# pse84 register map
Vendor: Infineon Technologies; Series: PSE84; File version: 1.0
CPU: CM33 r0p1, little endian, MPU, FPU, VTOR, 3 interrupt priority bits
Registers are 32-bit, read-write, reset 0x0 unless marked. A register's access mark holds for its fields unless they carry their own. Offsets are from the block's base; [hi:lo] are bit positions; lines under a group give offsets from that group; {n}, {i} and the like mark numbered series; 'fields as' and 'values as' point back to an identical list; <NAME> marks a mode.

## SMIF0 (part 3 of 3) — SMIF subsystem (1 SMIF cores, no bridge, 1 cache_block and 1 Q_LPI expander)
Base 0x44440000
Same registers: SMIF1 0x44480000
0x20000 CORE group — Serial Memory Interface
  {0x800+0x80*j} DEVICE[{j}] (j=0..3) group — Device (only used for XIP acceses)
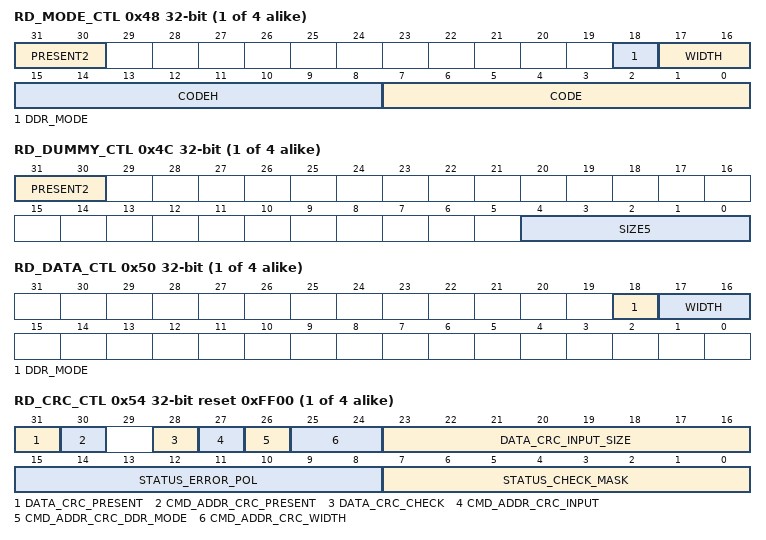
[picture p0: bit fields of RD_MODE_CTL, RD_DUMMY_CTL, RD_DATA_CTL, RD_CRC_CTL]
    0x48 RD_MODE_CTL — Read mode control
      [31:30] PRESENT2 — Presence of mode field: '0': not present '1': present (1 Byte) '2': present (2 Byte for OPI) Note: For octal data transfer with DDR mode (WIDTH='3' and DDR_MODE='1') this field needs to be set to PRESENT2='2' to generate a mode field (or to PRESENT2='0').
      [18] DDR_MODE — Mode of transfer rate.
      [17:16] WIDTH — Width of transfer.
      [15:8] CODEH — Mode high byte code. This field specifies the most significant mode byte, sent before the least significant mode byte (CODE). It is only used when PRESENT2 = '2'.
      [7:0] CODE — Mode byte code. Note: If a mode field is present (PRESENT='1') for octal data transfer with DDR mode (WIDTH='3' and DDR_MODE='1') the CODE is sent twice.
    0x4C RD_DUMMY_CTL — Read dummy control
      [31:30] PRESENT2 — Presence of dummy cycles: '0': not present '1': present '2': present - Dummy cycles are doubled when RWDS refresh indicator is high during CA cycle. (HyperRAM variable latency mode) Notes: - If transmitting command, address and mode fields in SDR mode (driving data between falling edges of spihb_clk_out) and the memory is driving read data in DDR mode (based on memory type and transmitted command), then there must be at least 1 latency / dummy cycle specified (RD_DUMMY_CTL.PRESENT2 > 0') to prevent controller and memory driving data signals at the same time. The same is true for the theoretical (practically irrelevant case) of transmitting at least one of the command, address and mode fields in DDR mode but receiving data from the memory in SDR mode. - When using the RWDS / DQS based capturing scheme (CTL2.RX_CAPTURE_MODE), then there is a minimum number of latency / dummy cycles required (RD_DUMMY_CTL.PRESENT2 > 0). For the Hyperbus protocol (DDR_CTL.SIZE3=7) at least 1 latency / dummy cycle has to be specified, for SPI with DQS capturing at least 2 latency / dummy cycles need to be selected (RD_DUMMY_CTL.SIZE5 > 0, exception see following note). - In case of falling edge RWDS / DQS capturing (CTL2.RX_CAPTURE_MODE) and SDR mode, SW should reduce the number of dummy cycles by 1 compared to the latency cycles required by the memory device. -DDR read commands need at least one dummy cycle -For Hyperbus, set RD DUMMY_CTL.SIZE5=initial latency cycles-2
      [4:0] SIZE5 — Number of dummy cycles (minus 1): '0': 1 cycles ... '31': 32 cycles. Note: this field specifies dummy cycles, not dummy Bytes!
    0x50 RD_DATA_CTL — Read data control
      [18] DDR_MODE — Mode of transfer rate.
      [17:16] WIDTH — Width of transfer.
    0x54 RD_CRC_CTL reset 0xFF00 — Read Bus CRC control
      [31] DATA_CRC_PRESENT — Presence of data CRC field: '0': not present '1': present Note: Width and data transfer mode (SDR or DDR) of read data CRC fields are the same as for the associated read data fields, i.e. are specified by RD_DATA_CTL.WIDTH and RD_DATA_CTL.DDR_MODE.
      [30] CMD_ADDR_CRC_PRESENT — Presence of command / address CRC field: '0': not present '1': present Note: For octal data transfer with DDR mode (RD_CRC_CTL.WIDTH='3' and RD_CRC_CTL.DDR_MODE='1') the command / address CRC byte is sent twice, otherwise the command / address CRC byte is only sent once.
      [28] DATA_CRC_CHECK
      [27] CMD_ADDR_CRC_INPUT — Specifies which fields are included in the command / address CRC generation. '0': The command / address CRC field is generated over the address and (if present) mode fields only. '1': The command / address CRC field is generated over the command, address and (if present) mode fields.
      [26] CMD_ADDR_CRC_DDR_MODE — Mode of transfer rate of command / address CRC field.
      [25:24] CMD_ADDR_CRC_WIDTH — Width of command / address CRC field.
      [23:16] DATA_CRC_INPUT_SIZE — Number of input data bytes for CRC generation (minus 1), i.e. number of data bytes over which the data CRC field is generated (minus 1): '0': 1 byte ... '255': 256 bytes. Note: For octal data transfer with DDR mode (RD_DATA_CTL.WIDTH='3' and RD_DATA_CTL.DDR_MODE='1') the number of bytes for CRC generation must be even (i.e. DATA_CRC_INPUT_SIZE must be odd).
      [15:8] STATUS_ERROR_POL — Specifies the polarity of the Functional Safety Status field bits. There is 1 polarity bit for each Functional Safety Status bit. '0': The associated Functional Safety Status bit is active-low. '1': The associated Functional Safety Status bit is active-high.
      [7:0] STATUS_CHECK_MASK — Specifies which of the Functional Safety Status field bits are checked. There is 1 mask bit for each Functional Safety Status bit. '0': The associated Functional Safety Status bit is not checked. '1': The associated Functional Safety Status bit is checked. If the received Funciontal Safety Status bit = Functional Safety Status Error Polarity (STATUS_ERROR_POLARITY), then a Functional Safety Status error interrupt and a XIP bus error response is generated.
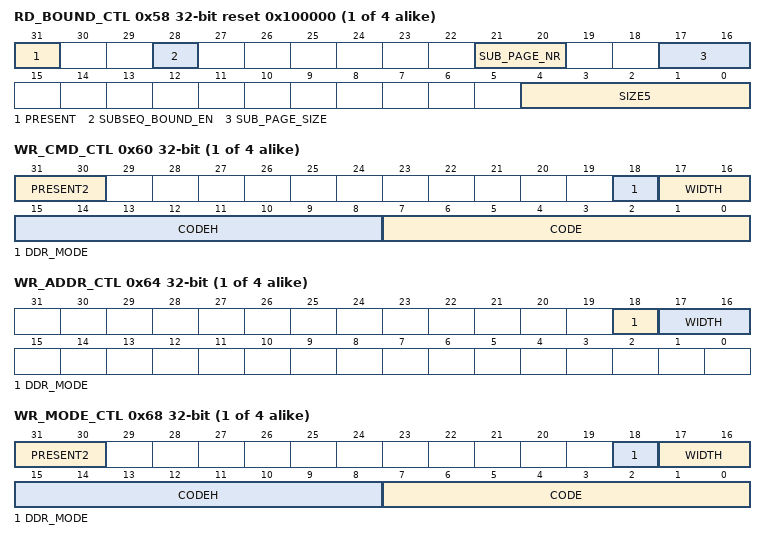
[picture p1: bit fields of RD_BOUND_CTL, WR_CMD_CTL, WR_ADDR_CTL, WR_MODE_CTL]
    0x58 RD_BOUND_CTL reset 0x100000 — Read boundary control
      [31] PRESENT — Presence of first page boundary latency cycles: '0': not present '1': present
      [28] SUBSEQ_BOUND_EN — Enable subsequent page boundary latency cycles. '0': Disabled. The page crossing latency cycles are only generated when crossing the first page boundary (i.e. the first time when the SUB_PAGE_NRth sub page boundary is crossed, e.g. with 2 sub pages per page when the 2nd sub page boundary is crossed). '1': Enabled. The page crossing latency cycles are generated when crossing the first and subsequent page boundaries (i.e. every time when a SUB_PAGE_NRth sub page boundary is crossed, e.g. with 2 sub pages per page when the 2nd, 4th, 6th, ... sub page boundary is crossed). Note: This only applies when the number of base latency cycles (SIZE5+1) is greater than the size of a page (base_latency > page_size). Must be set to 0 otherwise.
      [21:20] SUB_PAGE_NR — Specifies the number of sub pages per page. '0': 1 sub pages per page, i.e. page_size = sub_page_size '1': 2 sub pages per page, i.e. page_size = 2 x sub_page_size '2': 4 sub pages per page, i.e. page_size = 4 x sub_page_size '3': 8 sub pages per page, i.e. page_size = 8 x sub_page_size
      [17:16] SUB_PAGE_SIZE — Specifies the size of a memory sub page 'sub_page_size'. '0': sub_page_size = 8 words = 16 bytes (default). '1': sub_page_size = 16 words = 32 bytes. '2': sub_page_size = 32 words = 64 bytes. '3': sub_page_size = 64 words = 128 bytes.
      [4:0] SIZE5 — Number of base latency cycles (minus 1) used for calculating the number of fist page boundary crossing latency cycles: '0': base_latency = 1 cycles ... '31': base_latency = 32 cycles. The actual latency cycles when crossing the first page boundary depend on the start address of the transaction and is calculated as follows: if ((page_size - base_latency) < Start_Addr & (sub_page_size - 1)) { ((Start_Addr & (sub_page_size - 1)) - page_size + base_latency) } else { 0 }
    0x60 WR_CMD_CTL — Write command control
      [31:30] PRESENT2 — Presence of command field: '0': not present '1': present (1 Byte) '2': present (2 Byte for OPI) Note: For octal data transfer with DDR mode (WIDTH='3' and DDR_MODE='1') either the HB protocol needs to be selected (by ADDR_CTL.SIZE3='7') or this field needs to be set to PRESENT2='2'.
      [18] DDR_MODE — Mode of transfer rate.
      [17:16] WIDTH — Width of transfer.
      [15:8] CODEH — Command high byte code. This field specifies the most significant command byte, sent before the least significant command byte (CODE). It is only used when PRESENT2 = '2'.
      [7:0] CODE — Command byte code.
    0x64 WR_ADDR_CTL — Write address control
      fields as CORE.DEVICE[0].RD_DATA_CTL
    0x68 WR_MODE_CTL — Write mode control
      [31:30] PRESENT2 — Presence of mode field: '0': not present '1': present (1 Byte) '2': present (2 Byte for OPI) Note: For octal data transfer with DDR mode (WIDTH='3' and DDR_MODE='1') this field needs to be set to PRESENT2='2' to generate a mode field (or to PRESENT2='0').
      [18] DDR_MODE — Mode of transfer rate.
      [17:16] WIDTH — Width of transfer.
      [15:8] CODEH — Mode high byte code. This field specifies the most significant mode byte, sent before the least significant mode byte (CODE). It is only used when PRESENT2 = '2'.
      [7:0] CODE — Mode byte code.
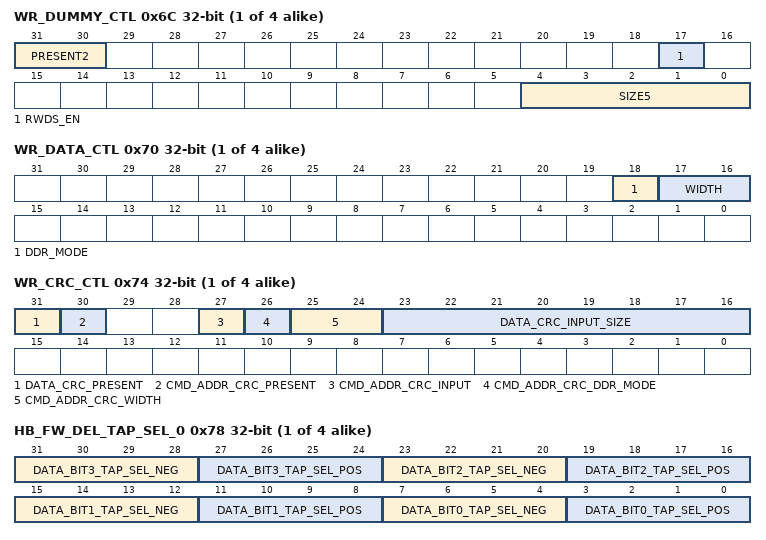
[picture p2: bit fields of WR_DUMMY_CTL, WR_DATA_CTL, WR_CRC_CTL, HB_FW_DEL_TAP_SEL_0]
    0x6C WR_DUMMY_CTL — Write dummy control
      [31:30] PRESENT2 — Presence of dummy cycles: '0': not present '1': present '2': present - Dummy cycles are doubled when RWDS refresh indicator is high during CA cycle. (HyperRAM variable latency mode)
      [17] RWDS_EN — Read-Write-Data-Strobe Enable. Specifies whether the RWDS output signal should be driven starting in the last dummy cycle until DESELECT. This is needed for write transactions with byte masking via RWDS (e.g. Hyperbus). '0': do not drive RWDS output '1': drive RWDS output starting in last dummy cycle until DESELECT Note: this field is located in the WR_DUMMY_CTL register (and not in the WR_DATA_CTL register) since the RWDS signal needs to be driven already in the last dummy cycle.
      [4:0] SIZE5 — Number of dummy cycles (minus 1): '0': 1 cycles ... '31': 32 cycles.
    0x70 WR_DATA_CTL — Write data control
      fields as CORE.DEVICE[0].RD_DATA_CTL
    0x74 WR_CRC_CTL — Write Bus CRC control
      [31] DATA_CRC_PRESENT — Presence of data CRC field: '0': not present '1': present Note: Width and data transfer mode (SDR or DDR) of read data CRC fields are the same as for the associated read data fields, i.e. are specified by RD_DATA_CTL.WIDTH and RD_DATA_CTL.DDR_MODE. Note: For octal data transfer with DDR mode (RD_DATA_CTL.WIDTH='3' and RD_DATA_CTL.DDR_MODE='1') the data CRC byte is sent twice, otherwise the data CRC byte is only sent once.
      [30] CMD_ADDR_CRC_PRESENT — Presence of command / address CRC field: '0': not present '1': present Note: For octal data transfer with DDR mode (RD_CRC_CTL.WIDTH='3' and RD_CRC_CTL.DDR_MODE='1') the command / address CRC byte is sent twice, otherwise the command / address CRC byte is only sent once.
      [27] CMD_ADDR_CRC_INPUT — Specifies which fields are included in the command / address CRC generation. '0': The command / address CRC field is generated over the address and (if present) mode fields only. '1': The command / address CRC field is generated over the command, address and (if present) mode fields.
      [26] CMD_ADDR_CRC_DDR_MODE — Mode of transfer rate of command / address CRC field.
      [25:24] CMD_ADDR_CRC_WIDTH — Width of command / address CRC field.
      [23:16] DATA_CRC_INPUT_SIZE — Number of input data bytes for CRC generation (minus 1), i.e. number of data bytes over which the data CRC field is generated (minus 1): '0': 1 byte ... '255': 256 bytes. Note: For octal data transfer with DDR mode (WR_DATA_CTL.WIDTH='3' and WR_DATA_CTL.DDR_MODE='1') the number of bytes for CRC generation must be even (i.e. DATA_CRC_INPUT_SIZE must be odd).
    0x78 HB_FW_DEL_TAP_SEL_0 — HB FW Calibration Delay Tap Select 0
      [31:28] DATA_BIT3_TAP_SEL_NEG — HB FW Calibration: Delay line tap select for spi_data[3], NEG Clock Phase (note the mapping of spi_data to IO in DEVICE.CTL.DATA_SEL). See DATA_BIT0_TAP_SEL.
      [27:24] DATA_BIT3_TAP_SEL_POS — HB FW Calibration: Delay line tap select for spi_data[3], POS Clock Phase (note the mapping of spi_data to IO in DEVICE.CTL.DATA_SEL). See DATA_BIT0_TAP_SEL.
      [23:20] DATA_BIT2_TAP_SEL_NEG — HB FW Calibration: Delay line tap select for spi_data[2], NEG Clock Phase (note the mapping of spi_data to IO in DEVICE.CTL.DATA_SEL). See DATA_BIT0_TAP_SEL.
      [19:16] DATA_BIT2_TAP_SEL_POS — HB FW Calibration: Delay line tap select for spi_data[2], POS Clock Phase (note the mapping of spi_data to IO in DEVICE.CTL.DATA_SEL). See DATA_BIT0_TAP_SEL.
      [15:12] DATA_BIT1_TAP_SEL_NEG — HBs FW Calibration: Delay line tap select for spi_data[1], NEG Clock Phase (note the mapping of spi_data to IO in DEVICE.CTL.DATA_SEL). See DATA_BIT0_TAP_SEL.
      [11:8] DATA_BIT1_TAP_SEL_POS — HB FW Calibration: Delay line tap select for spi_data[1], POS Clock Phase (note the mapping of spi_data to IO in DEVICE.CTL.DATA_SEL). See DATA_BIT0_TAP_SEL.
      [7:4] DATA_BIT0_TAP_SEL_NEG — HB FW Calibration: Delay line tap select for spi_data[0], NEG Clock Phase (note the mapping of spi_data to IO in DEVICE.CTL.DATA_SEL). See DATA_BIT0_TAP_SEL.
      [3:0] DATA_BIT0_TAP_SEL_POS — HB FW Calibration tap select for spi_data[0], POS clock Phase (note the mapping of spi_data to IO in DEVICE.CTL.DATA_SEL).
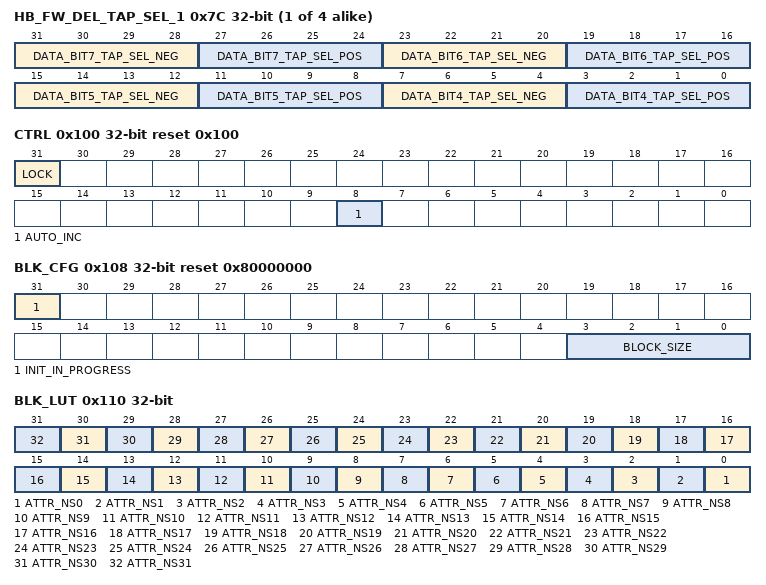
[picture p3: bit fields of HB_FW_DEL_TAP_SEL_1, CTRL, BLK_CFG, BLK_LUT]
    0x7C HB_FW_DEL_TAP_SEL_1 — HB FW Calibration Delay Tap Select 1
      [31:28] DATA_BIT7_TAP_SEL_NEG — HB FW Calibration: Delay line tap select for spi_data[7], NEG Clock Phase (note the mapping of spi_data to IO in DEVICE.CTL.DATA_SEL). See DATA_BIT0_TAP_SEL.
      [27:24] DATA_BIT7_TAP_SEL_POS — HB FW Calibration: Delay line tap select for spi_data[7], POS Clock Phase (note the mapping of spi_data to IO in DEVICE.CTL.DATA_SEL). See DATA_BIT0_TAP_SEL.
      [23:20] DATA_BIT6_TAP_SEL_NEG — HB FW Calibration: Delay line tap select for spi_data[6], NEG Clock Phase (note the mapping of spi_data to IO in DEVICE.CTL.DATA_SEL). See DATA_BIT0_TAP_SEL.
      [19:16] DATA_BIT6_TAP_SEL_POS — HB FW Calibration: Delay line tap select for spi_data[6], POS Clock Phase (note the mapping of spi_data to IO in DEVICE.CTL.DATA_SEL). See DATA_BIT0_TAP_SEL.
      [15:12] DATA_BIT5_TAP_SEL_NEG — HBs FW Calibration: Delay line tap select for spi_data[5], NEG Clock Phase (note the mapping of spi_data to IO in DEVICE.CTL.DATA_SEL). See DATA_BIT0_TAP_SEL.
      [11:8] DATA_BIT5_TAP_SEL_POS — HB FW Calibration: Delay line tap select for spi_data[5], POS Clock Phase (note the mapping of spi_data to IO in DEVICE.CTL.DATA_SEL). See DATA_BIT0_TAP_SEL.
      [7:4] DATA_BIT4_TAP_SEL_NEG — HB FW Calibration: Delay line tap select for spi_data[4], NEG Clock Phase (note the mapping of spi_data to IO in DEVICE.CTL.DATA_SEL). See DATA_BIT0_TAP_SEL.
      [3:0] DATA_BIT4_TAP_SEL_POS — HB FW Calibration tap select for spi_data[4], POS clock Phase (note the mapping of spi_data to IO in DEVICE.CTL.DATA_SEL).
  0x3000 AXI group — Serial Memory Interface
    0x00 MPC group — MPC Memory Protection Controller registers
      0x00 CFG — Config register with error response, RegionID PPC_MPC_MAIN is the security owner PC. The error response configuration is located in CFG.RESPONSE, only one such configuration exists applying to all protection contexts in the system.
        [4] RESPONSE — Response Configuration for Security and PC violations 0: Read-Zero Write Ignore (RAZ/WI) 1: Bus Error
      0x100 CTRL reset 0x100 — Control register with lock bit and auto-increment only (Separate CTRL for each PC depends on access_pc)
        [31] LOCK — Security lockdown for this protection context. Software can set this bit but not clear it once set. When set, write operations to BLK_LUT are not possible from this protection context. Setting LOCK also blocks writes to CTRL itself (for that PC copy). All writes are ignored.
        [8] AUTO_INC — Auto-increment BLK_IDX by 1 for this protection context as a side effect of each read/write access to BLK_LUT
      0x104 BLK_MAX ro — Max value of block-based index register
        [31:0] VALUE — Maximum value of block-based index register. The number and size blocks in an MPC is design time configurable and for embedded memories defaults to covering the entire memory using 4kB blocks; See product datasheet for details on protection of external memories.
      0x108 BLK_CFG ro reset 0x80000000 — Block size & initialization in progress
        [31] INIT_IN_PROGRESS — During initialization INIT_IN_PROGRESS is '1' and MMIO register accesses to BLK_LUT is blocked (BLK_IDX increment is also ignored). The block attributes are retained in DeepSleep (and obviously Active) power mode. Initialization is only required from a power mode in which the block attributes are not retained. E.g., initialization is required for a cold boot (after a Power-on-Reset). HW initializes the block attributes: the NS attributes are set to '0' (secure), the R attributes are set to '1' (read access allowed) and the W attributes are set to '1' (write access allowed). During initialization, the MPC supports memory accesses (memory accesses are NOT blocked) with the initialization block attribute values as mentioned above. This e.g. allows MPC initialization to proceed in parallel with boot program memory accesses (as opposed to serializing the two), improving device boot time.
        [3:0] BLOCK_SIZE — Block size of individually protected blocks (0: 32B, 1: 64B, ... up to 15: 1MB) Block size= (1<<(BLOCK_SIZE+5)) The number and size blocks in an MPC is design time configurable and for embedded memories defaults to covering the entire memory using 4kB blocks; see product datasheet for details on protection of external memories.
      0x10C BLK_IDX — Index of 32-block group accessed through BLK_LUT (Separate IDX for each PC depending on access_pc)
        [31:0] VALUE — Index value for accessing block-based lookup table using BLK_LUT. Programming out of LUT range is an user error and it loops back to '0' once overflow occurs.
      0x110 BLK_LUT — NS status for 32 blocks at BLK_IDX with PC=<access_pc>
        [n] ATTR_NS{n} (n=0..31) — NS bit for block {n} based on BLK_IDX
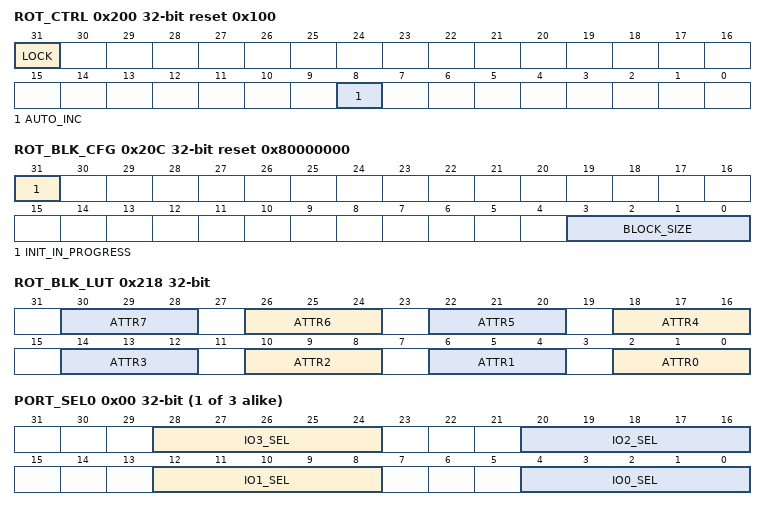
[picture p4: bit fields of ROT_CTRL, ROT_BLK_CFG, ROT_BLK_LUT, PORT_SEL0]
      0x200 ROT_CTRL reset 0x100 — Control register with lock bit and auto-increment only
        [31] LOCK — Security lockdown for the root-of-trust configuration registers. Software can set this bit but not clear it once set. When set, write operations to ROT_BLK_LUT are not possible. Write is ignored.
        [8] AUTO_INC — Auto-increment BLK_IDX by 1 for each read/write of ROT_BLK_LUT
      0x208 ROT_BLK_MAX ro — Max value of block-based index register for ROT
        [31:0] VALUE — Maximum value of block-based index register. The number and size blocks in an MPC is design time configurable and for embedded memories defaults to covering the entire memory using 4kB blocks; see product datasheet for details on protection of external memories.
      0x20C ROT_BLK_CFG ro reset 0x80000000 — Same as BLK_CFG
        [31] INIT_IN_PROGRESS — During initialization INIT_IN_PROGRESS is '1' and MMIO register accesses to ROT_BLK_LUT is RAZWI. The block attributes are retained in DeepSleep (and obviously Active) power mode. Initialization is only required from a power mode in which the block attributes are not retained. E.g., initialization is required for a cold boot (after a Power-on-Reset). HW initializes the block attributes: the NS attributes are set to '0' (secure), the R attributes are set to '1' (read access allowed) and the W attributes are set to '1' (write access allowed). During initialization, the MPC supports memory accesses (memory accesses are NOT blocked) with the initialization block attribute values as mentioned above. This e.g. allows MPC initialization to proceed in parallel with boot program memory accesses (as opposed to serializing the two), improving device boot time.
        [3:0] BLOCK_SIZE — Block size of individually protected blocks (0: 32B, 1: 64B, ...up to 15:1MB) Block size= (1<<(BLOCK_SIZE+5)) The number and size blocks in an MPC is design time configurable and for embedded memories defaults to covering the entire memory using 4kB blocks; see product datasheet for details on protection of external memories.
      0x210 ROT_BLK_IDX — Index of 8-block group accessed through ROT_BLK_LUT_*
        [31:0] VALUE — Index value for accessing block-based lookup table using ROT_BLK_LUT. Programming out of LUT range is an user error and it loops back to '0' once overflow occurs.
      0x214 ROT_BLK_PC — Protection context of 8-block group accesses through ROT_BLK_LUT
        [3:0] PC — Specify PC values for ROT_BLK_IDX and ROT_BLK_LUT
      0x218 ROT_BLK_LUT — (R,W,NS) bits for 8 blocks at ROT_BLK_IDX for PC=ROT_BKL_PC
        [4n+2:4n] ATTR{n} (n=0..7) — W/R/NS bits for block {n} indicated by ROT_BLK_IDX for ROT_BLK_PC PC
  0x4000 SMIF_HSIOM group — IO Matrix (IOM)
    {0x0+0x10*k} SMIF_PRT[{k}] (k=0..2) group — HSIOM port registers
      0x00 PORT_SEL0 — Port selection 0
        [28:24] IO3_SEL — Selects connection for IO pin 3 route.
        [20:16] IO2_SEL — Selects connection for IO pin 2 route.
        [12:8] IO1_SEL — Selects connection for IO pin 1 route.
        [4:0] IO0_SEL — Selects connection for IO pin 0 route.
          0=GPIO (GPIO controls 'out'); 1=GPIO_DSI (GPIO controls 'out', DSI controls 'output enable'); 2=DSI_DSI (DSI controls 'out' and 'output enable'); 3=DSI_GPIO (DSI controls 'out', GPIO controls 'output enable'); 4=AMUXA (Analog mux bus A); 5=AMUXB (Analog mux bus B); 6=AMUXA_DSI (Analog mux bus A, DSI control); 7=AMUXB_DSI (Analog mux bus B, DSI control); {v}=ACT_{v-8} (Active functionality {v-8}) (v=8..11); {v}=DS_{v-12} (DeepSleep functionality {v-12}) (v=12..15); {v}=ACT_{v-12} (Active functionality {v-12}) (v=16..25); 26=ACT_14 (Active functionality 14. Use this setting for AUX functionality (PRT0_PORT_SEL0 for DATA LSBs).); 27=ACT_15 (Active functionality 15. Use this setting for SMIF functionality (PRT0_PORT_SEL0 for DATA LSBs, PRT1_PORT_SEL0 for CLK, PRT2_PORT_SEL0 for RWDS).); {v}=DS_{v-24} (DeepSleep functionality {v-24}) (v=28..31)
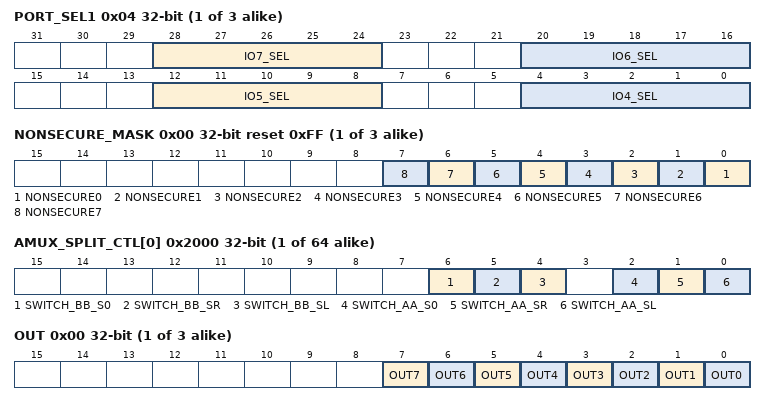
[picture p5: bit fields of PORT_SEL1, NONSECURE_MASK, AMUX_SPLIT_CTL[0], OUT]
      0x04 PORT_SEL1 — Port selection 1
        [28:24] IO7_SEL — Selects connection for IO pin 7 route.
        [20:16] IO6_SEL — Selects connection for IO pin 6 route.
        [12:8] IO5_SEL — Selects connection for IO pin 5 route.
        [4:0] IO4_SEL — Selects connection for IO pin 4 route. See PORT_SEL0 for connection details. PRT0_PORT_SEL1 is used for DATA MSBs.
    {0x1000+0x10*k} SMIF_SECURE_PRT[{k}] (k=0..2) group — HSIOM secure attribute port registers
      0x00 NONSECURE_MASK reset 0xFF
        [n] NONSECURE{n} (n=0..7) — Non-secure attribute for IO{n}. 0 - Allows Secure access only. 1 - Allows Non-secure access only.
    {0x2000+4k} AMUX_SPLIT_CTL[{k}] (k=0..63) — AMUX splitter cell control
      [6] SWITCH_BB_S0 — T-switch control for AMUXBUSB vssa/ground switch.
      [5] SWITCH_BB_SR — T-switch control for Right AMUXBUSB switch.
      [4] SWITCH_BB_SL — T-switch control for Left AMUXBUSB switch.
      [2] SWITCH_AA_S0 — T-switch control for AMUXBUSA vssa/ground switch: '0': switch open. '1': switch closed.
      [1] SWITCH_AA_SR — T-switch control for Right AMUXBUSA switch: '0': switch open. '1': switch closed.
      [0] SWITCH_AA_SL — T-switch control for Left AMUXBUSA switch: '0': switch open. '1': switch closed.
    {0x2200+4k} MONITOR_CTL_{k} (k=0..3) — Power/Ground Monitor cell control {k}
      [31:0] MONITOR_EN — control for switch, which connects the power/ground supply to AMUXBUS_A/B respectively when switch is closed: '0': switch open. '1': switch closed.
  0x10000 SMIF_GPIO group — IO port control/configuration
    {0x0+0x80*k} SMIF_PRT[{k}] (k=0..2) group — GPIO port registers
      0x00 OUT — Port output data register
        [n] OUT{n} (n=1..7) — IO output data for pin {n}
        [0] OUT0 — IO output data for pin 0 '0': Output state set to '0' '1': Output state set to '1'
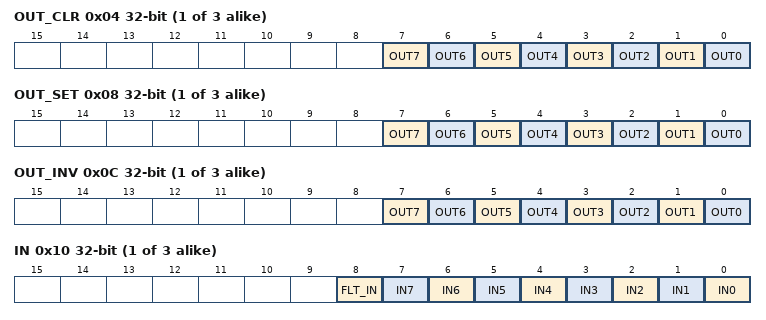
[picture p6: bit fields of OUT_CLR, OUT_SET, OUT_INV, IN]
      0x04 OUT_CLR — Port output data clear register
        [n] OUT{n} (n=1..7) — IO clear output for pin {n}
        [0] OUT0 — IO clear output for pin 0: '0': Output state not affected. '1': Output state set to '0'.
      0x08 OUT_SET — Port output data set register
        [n] OUT{n} (n=1..7) — IO set output for pin {n}
        [0] OUT0 — IO set output for pin 0: '0': Output state not affected. '1': Output state set to '1'.
      0x0C OUT_INV — Port output data invert register
        [n] OUT{n} (n=1..7) — IO invert output for pin {n}
        [0] OUT0 — IO invert output for pin 0: '0': Output state not affected. '1': Output state inverted ('0' => '1', '1' => '0').
      0x10 IN ro — Port input state register
        [8] FLT_IN — Reads of this register return the logical state of the filtered pin as selected in the INTR_CFG.FLT_SEL register.
        [n] IN{n} (n=1..7) — IO pin state for pin {n}
        [0] IN0 — IO pin state for pin 0 '0': Low logic level present on pin. '1': High logic level present on pin.
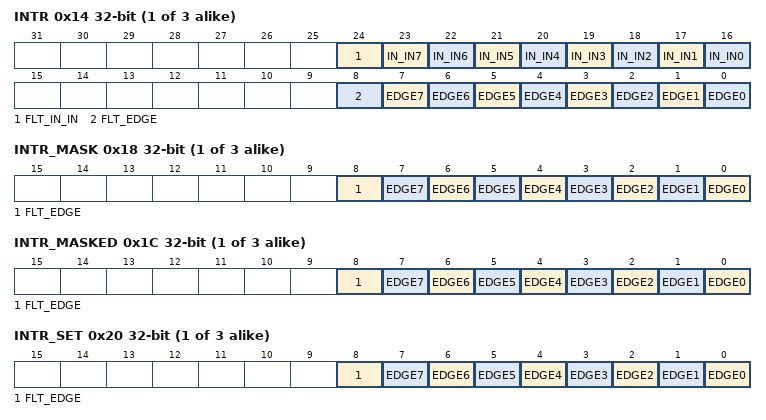
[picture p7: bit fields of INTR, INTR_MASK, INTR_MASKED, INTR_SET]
      0x14 INTR — Port interrupt status register
        [24] FLT_IN_IN ro — Filtered pin state for pin selected by INTR_CFG.FLT_SEL
        [n+16] IN_IN{n} ro (n=0..7) — IO pin state for pin {n}
        [8] FLT_EDGE — Edge detected on filtered pin selected by INTR_CFG.FLT_SEL
        [n] EDGE{n} (n=1..7) — Edge detect for IO pin {n}
        [0] EDGE0 — Edge detect for IO pin 0 '0': No edge was detected on pin. '1': An edge was detected on pin.
      0x18 INTR_MASK — Port interrupt mask register
        [8] FLT_EDGE — Masks edge interrupt on filtered pin selected by INTR_CFG.FLT_SEL
        [n] EDGE{n} (n=1..7) — Masks edge interrupt on IO pin {n}
        [0] EDGE0 — Masks edge interrupt on IO pin 0 '0': Pin interrupt forwarding disabled '1': Pin interrupt forwarding enabled
      0x1C INTR_MASKED ro — Port interrupt masked status register
        [8] FLT_EDGE — Edge detected and masked on filtered pin selected by INTR_CFG.FLT_SEL
        [n] EDGE{n} (n=1..7) — Edge detected and masked on IO pin {n}
        [0] EDGE0 — Edge detected AND masked on IO pin 0 '0': Interrupt was not forwarded to CPU '1': Interrupt occurred and was forwarded to CPU
      0x20 INTR_SET — Port interrupt set register
        [8] FLT_EDGE — Sets edge detect interrupt for filtered pin selected by INTR_CFG.FLT_SEL
        [n] EDGE{n} (n=1..7) — Sets edge detect interrupt for IO pin {n}
        [0] EDGE0 — Sets edge detect interrupt for IO pin 0 '0': Interrupt state not affected '1': Interrupt set
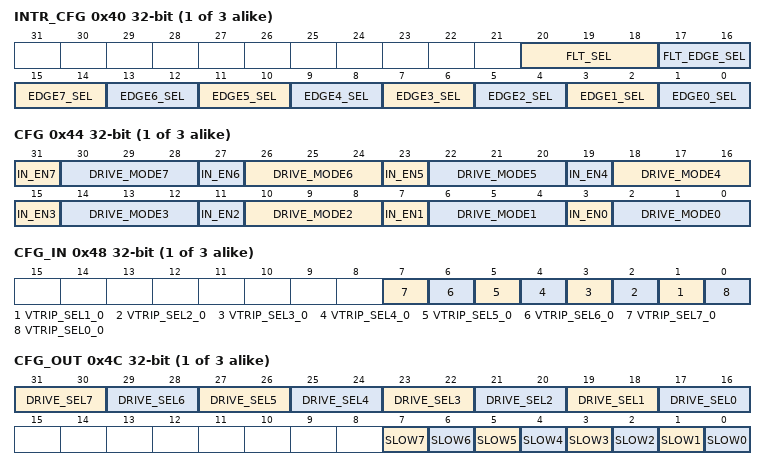
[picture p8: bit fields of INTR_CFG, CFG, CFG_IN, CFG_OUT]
      0x40 INTR_CFG — Port interrupt configuration register
        [20:18] FLT_SEL — Selects which pin is routed through the 50ns glitch filter to provide a glitch-safe interrupt.
        [17:16] FLT_EDGE_SEL — Sets which edge will trigger an IRQ for the glitch filtered pin (selected by INTR_CFG.FLT_SEL
          0=DISABLE (Disabled); 1=RISING (Rising edge); 2=FALLING (Falling edge); 3=BOTH (Both rising and falling edges)
        [2n+1:2n] EDGE{n}_SEL (n=1..7) — Sets which edge will trigger an IRQ for IO pin {n}
        [1:0] EDGE0_SEL — Sets which edge will trigger an IRQ for IO pin 0
          values as FLT_EDGE_SEL
      0x44 CFG — Port configuration register
        [4n+3] IN_EN{n} (n=1..7) — Enables the input buffer for IO pin {n}
        [30:28] DRIVE_MODE7 — The GPIO drive mode for IO pin 7
        [26:24] DRIVE_MODE6 — The GPIO drive mode for IO pin 6
        [22:20] DRIVE_MODE5 — The GPIO drive mode for IO pin 5
        [18:16] DRIVE_MODE4 — The GPIO drive mode for IO pin4
        [14:12] DRIVE_MODE3 — The GPIO drive mode for IO pin 3
        [10:8] DRIVE_MODE2 — The GPIO drive mode for IO pin 2
        [6:4] DRIVE_MODE1 — The GPIO drive mode for IO pin 1
        [3] IN_EN0 — Enables the input buffer for IO pin 0. This bit should be cleared when analog signals are present on the pin to avoid crowbar currents. The output buffer can be used to drive analog signals high or low without issue. '0': Input buffer disabled '1': Input buffer enabled
        [2:0] DRIVE_MODE0 — The GPIO drive mode for IO pin 0. Resistive pull-up and pull-down is selected in the drive mode. Note: when initializing IO's that are connected to a live bus (such as I2C), make sure the peripheral and HSIOM (HSIOM_PRT_SELx) is properly configured before turning the IO on here to avoid producing glitches on the bus. Note: that peripherals other than GPIO & UDB/DSI directly control both the output and output-enable of the output buffer (peripherals can drive strong 0 or strong 1 in any mode except OFF='0'). Note: D_OUT, D_OUT_EN are pins of GPIO cell.
          0=CFG3_EN (Enables CFG3.Bit 0 to control Port Pin 0.); 1=RSVD (N/A); 2=PULLUP (Resistive pull up); 3=PULLDOWN (Resistive pull down); 4=OD_DRIVESLOW (Open drain, drives low); 5=OD_DRIVESHIGH (Open drain, drives high); 6=STRONG (Strong D_OUTput buffer); 7=PULLUP_DOWN (Pull up or pull down)
      0x48 CFG_IN — Port input buffer configuration register
        [n] VTRIP_SEL{n}_0 (n=1..7) — Configures the pin {n} input buffer mode (trip points and hysteresis)
        [0] VTRIP_SEL0_0 — Configures the pin 0 input buffer mode (trip points and hysteresis)
          0=CMOS (Input buffer compatible with CMOS and I2C interfaces); 1=TTL (Input buffer compatible with TTL and MediaLB interfaces)
      0x4C CFG_OUT — Port output buffer configuration register
        [2n+17:2n+16] DRIVE_SEL{n} (n=1..7) — Sets the GPIO drive strength for IO pin {n}
        [17:16] DRIVE_SEL0 — Sets the GPIO drive strength for IO pin 0
          0=DRIVE_SEL_ZERO (N/A); 1=DRIVE_SEL_ONE (N/A); 2=DRIVE_SEL_TWO (N/A); 3=DRIVE_SEL_THREE (N/A)
        [n] SLOW{n} (n=1..7) — Enables slow slew rate for IO pin {n}
        [0] SLOW0 — Enables slow slew rate for IO pin 0 '0': Fast slew rate '1': Slow slew rate
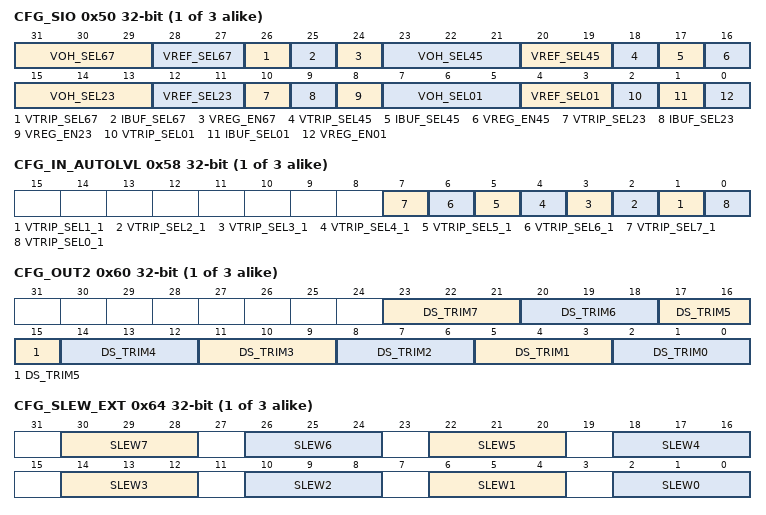
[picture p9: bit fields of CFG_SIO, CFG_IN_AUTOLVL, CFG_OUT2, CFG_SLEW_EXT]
      0x50 CFG_SIO — Port SIO configuration register
        [31:29] VOH_SEL67
        [28:27] VREF_SEL67
        [26] VTRIP_SEL67
        [25] IBUF_SEL67
        [24] VREG_EN67
        [23:21] VOH_SEL45
        [20:19] VREF_SEL45
        [18] VTRIP_SEL45
        [17] IBUF_SEL45
        [16] VREG_EN45
        [15:13] VOH_SEL23
        [12:11] VREF_SEL23
        [10] VTRIP_SEL23
        [9] IBUF_SEL23
        [8] VREG_EN23
        [7:5] VOH_SEL01 — Selects trip-point of input buffer. In single ended input buffer mode (IBUF01_SEL = '0'): 0: input buffer functions as a CMOS input buffer. 1: input buffer functions as a LVTTL input buffer. In differential input buffer mode (IBUF01_SEL = '1'): VTRIP_SEL=0: a) VREF_SEL=00, VOH_SEL=X -> Trip point=50 percent of vddio b) VREF_SEL=01, VOH_SEL=000 -> Trip point=Vohref (buffered) c) VREF_SEL=01, VOH_SEL=[1-7] -> Input buffer functions as CMOS input buffer. d) VREF_SEL=10/11, VOH_SEL=000 -> Trip point=Amuxbus_a/b (buffered) e) VREF_SEL=10/11, VOH_SEL=[1-7] -> Input buffer functions as CMOS input buffer. VTRIP_SEL=1: a) VREF_SEL=00, VOH_SEL=X -> Trip point=40 percent of vddio b) VREF_SEL=01, VOH_SEL=000 -> Trip point=0.5*Vohref c) VREF_SEL=01, VOH_SEL=[1-7] -> Input buffer functions as LVTTL input buffer. d) VREF_SEL=10/11, VOH_SEL=000 -> Trip point=0.5*Amuxbus_a/b (buffered) e) VREF_SEL=10/11, VOH_SEL=[1-7] -> Input buffer functions as LVTTL input buffer.
        [4:3] VREF_SEL01
        [2] VTRIP_SEL01
        [1] IBUF_SEL01
        [0] VREG_EN01 — The regulated output mode is selected ONLY if the CFG.DRIVE_MODE bits are set to the strong pull up (Z_1 = '5') mode If the CFG.DRIVE_MODE bits are set to any other mode the regulated output buffer will be disabled and the standard CMOS output buffer is used.
      0x58 CFG_IN_AUTOLVL — Port input buffer AUTOLVL configuration register for S40E GPIO
        [n] VTRIP_SEL{n}_1 (n=1..7) — Input buffer compatible with automotive (elevated Vil) interfaces.
        [0] VTRIP_SEL0_1 — Configures the input buffer mode (trip points and hysteresis) for S40E GPIO upper bit. Lower bit is still selected by CFG_IN.VTRIP_SEL0_0 field. This field is used along with CFG_IN.VTRIP_SEL0_0 field as below: {CFG_IN_AUTOLVL.VTRIP_SEL0_1,CFG_IN.VTRIP_SEL0_0}: 0,0: CMOS 0,1: TTL 1,0: input buffer is compatible with automotive. 1,1: input buffer is compatible with MediaLB.
          0=CMOS_OR_TTL (Input buffer compatible with CMOS/TTL interfaces as described in CFG_IN.VTRIP_SEL0_0.); 1=AUTO_OR_MediaLB (Input buffer compatible with AUTO/MediaLB (elevated Vil) interfaces when used along with CFG_IN.VTRIP_SEL0_0.)
      0x60 CFG_OUT2 — Port output buffer configuration register 2
        [3n+2:3n] DS_TRIM{n} (n=1..7) — Sets the Drive Select Trim for IO pin {n}
        [2:0] DS_TRIM0 — Sets the Drive Select Trim for IO pin 0 0 - Default (50ohms) 1 - 120ohms 2 - 90ohms 3 - 60ohms 4 - 50ohms 5 - 30ohms 6 - 20ohms 7 - 15ohms
          0=DEFAULT (N/A); 1=DS_120OHM (N/A); 2=DS_90OHM (N/A); 3=DS_60OHM (N/A); 4=DS_50OHM (N/A); 5=DS_30OHM (N/A); 6=DS_20OHM (N/A); 7=DS_15OHM (N/A)
      0x64 CFG_SLEW_EXT — Port output buffer slew extension configuration register
        [4n+2:4n] SLEW{n} (n=1..7) — Slew rate for IO pin {n}
        [2:0] SLEW0 — Enables slow slew rate for IO pin 0 '0': Fast slew rate '1': Slow slew rate
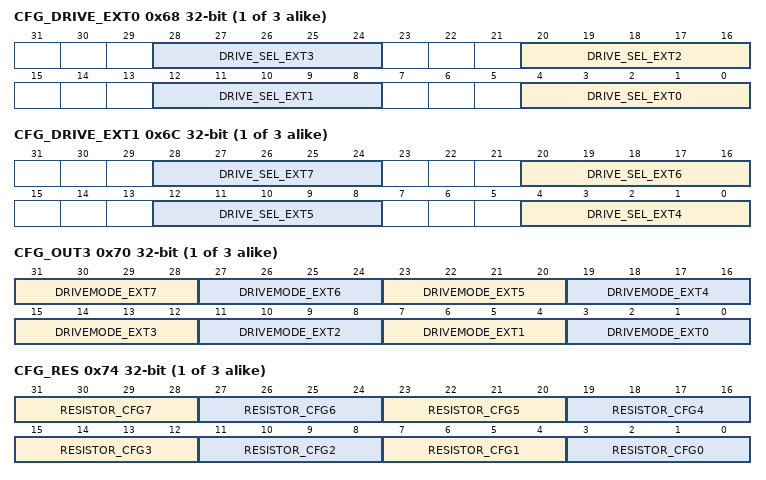
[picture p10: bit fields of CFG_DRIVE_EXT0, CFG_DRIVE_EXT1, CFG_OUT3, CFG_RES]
      0x68 CFG_DRIVE_EXT0 — Port output buffer drive sel extension configuration register
        [8n+4:8n] DRIVE_SEL_EXT{n} (n=0..3) — Sets the GPIO drive strength for IO pin {n}
      0x6C CFG_DRIVE_EXT1 — Port output buffer drive sel extension configuration register
        [8n-28:8n-32] DRIVE_SEL_EXT{n} (n=4..7) — Sets the GPIO drive strength for IO pin {n}
      0x70 CFG_OUT3 — Port output buffer configuration register 3
        [4n+3:4n] DRIVEMODE_EXT{n} (n=1..7) — Sets the Drive mode for pin {n}.
        [3:0] DRIVEMODE_EXT0 — Sets the Drive mode for pin 0. This fields are valid only if CFG.DRIVE_MODE0=0. See the bit value definitions below for functions.
          0=HIGHZ (Hi Z data_out_en=1: data_out=X-> HIZ, data_out_en=0, data_out=X-> HiZ); 1=PUPD (Strong drive 0/1 when enabled - else pull_up and pull_down both enabled data_out_en=1: data_out=1/0->Strong 1/0, data_out_en=0, data_out=X-> Pull Up & Pull Down); 2=PULLUP (Strong drive 0/1 when enabled - else pull_up enabled data_out_en=1: data_out= 1/0->Strong 1/0, data_out_en=0, data_out=X-> Pull Up); 3=PULLDOWN (Strong drive 0/1 when enabled - else pull_down enabled data_out_en=1: data_out=1/0->Strong 1/0 , data_out_en=0, data_out=X-> Pull Down); 4=OE0_HIZHIZ_0 (Strong drive 0/1 when enabled - else HIZ data_out_en=1: data_out=1/0-> Strong 1/0, data_out_en=0, data_out=X-> HiZ); 5=OE0_HIZHIZ_1 (Strong drive 0/1 when enabled - else HIZ data_out_en=1: data_out=1/0-> Strong 1/0, data_out_en=0, data_out=X-> HiZ); 6=OE0_HIZHIZ_2 (Strong drive 0/1 when enabled - else HIZ data_out_en=1: data_out=1/0-> Strong 1/0, data_out_en=0, data_out=X-> HiZ); 7=OE0_PUPD (Strong drive 0/1 when enabled else data_out driven by pull_up or pull _down following data_out data_out_en=1: data_out=1/0-> Strong 1/0, data_out_en=0, data_out=0-> pull_down, data_out_en=0,data_out=1->pull_up); 8=OE0_PUHIZ (Strong drive 0/1 when enabled else data_out driven by pull_up or HiZ following data_out data_out_en=1: data_out=1/0-> Strong 1/0, data_out_en=0, data_out=0-> pull_down, data_out_en=0,data_out=1->pull_up)
      0x74 CFG_RES — Port resistor configuration register 3
        [4n+3:4n] RESISTOR_CFG{n} (n=1..7) — Sets resistor value in IO cell for pin 1.
        [3:0] RESISTOR_CFG0 — Sets resistor value in IO cell for pin 1. - 50K pullup is NOT controlled by these bits. Used in conjuntion with CFG_OUT3[N]=OE0_PUHIZ (8).
          0=I3C_PU_DISABLE (Disable additional Pull-ups); 7=I3C_PU_570 (Pull-up 570 ohms); 6=I3C_PU_720 (Pull-up 720 Ohms); 5=I3C_PU_840 (Pull-up 840 Ohms); 3=I3C_PU_1100 (Pull-up 1100 Ohms); 4=I3C_PU_1200 (Pull-up 1200 Ohms); 2=I3C_PU_1800 (Pull-up 1800 Ohms); 1=I3C_PU_2800 (Pull-up 2800 Ohms)
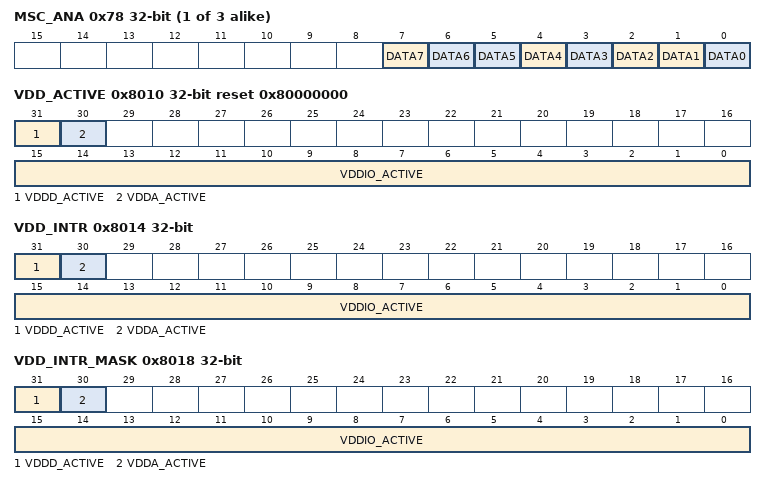
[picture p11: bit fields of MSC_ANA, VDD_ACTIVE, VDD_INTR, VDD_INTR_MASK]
      0x78 MSC_ANA — Port MSCv3 AMUX enable
        [7] DATA7 — IO pad 7 MSC_ANA_EN
        [6] DATA6 — IO pad 6 MSC_ANA_EN.
        [n] DATA{n} (n=2..5) — IO pad {n} MSC_ANA_EN
        [1] DATA1 — IO pad 1 MSC_ANA_EN.
        [0] DATA0 — IO pad 0 MSC_ANA_EN
    0x7000 SEC_INTR_CAUSE0 ro — Secure Interrupt port cause register 0
      [31:0] PORT_INT — Each IO port has an associated bit field in this register. The bit field reflects the IO port's interrupt line (bit field i reflects 'gpio_interrupts[i]' for IO port i). The register is used when the system uses a combined interrupt line 'gpio_interrupt'. The software ISR reads the register to determine which IO port(s) is responsible for the combined interrupt line. Once, the IO port(s) is determined, the IO port's GPIO_PRT_INTR register is read to determine the IO pin(s) in the IO port that caused the interrupt. '0': Port has no pending interrupt '1': Port has pending interrupt
    {0x7000+4k} SEC_INTR_CAUSE{k} ro (k=1..3) — Secure Interrupt port cause register {k}
      [31:0] PORT_INT — Each IO port has an associated bit field in this register. The bit field reflects the IO port's interrupt line (bit field i reflects 'gpio_interrupts[i]' for IO port i). The register is used when the system uses a combined interrupt line 'gpio_interrupt'. The software ISR reads the register to determine which IO port(s) is responsible for the combined interrupt line. Once, the IO port(s) is determined, the IO port's GPIO_PORT_INTR register is read to determine the IO pin(s) in the IO port that caused the interrupt. '0': Port has no pending interrupt '1': Port has pending interrupt
    0x8000 INTR_CAUSE0 ro — Interrupt port cause register 0
      fields as CORE.SMIF_GPIO.SEC_INTR_CAUSE0
    {0x8000+4k} INTR_CAUSE{k} ro (k=1..3) — Interrupt port cause register {k}
      fields as CORE.SMIF_GPIO.SEC_INTR_CAUSE1
    0x8010 VDD_ACTIVE ro reset 0x80000000 — Extern power supply detection register
      [31] VDDD_ACTIVE — This bit indicates presence of the VDDD supply. This bit will always read-back 1. The VDDD supply has robust brown-out protection monitoring and it is not possible to read back this register without a valid supply. (This bit is used in certain test-modes to observe the brown-out detector status.)
      [30] VDDA_ACTIVE — Same as VDDIO_ACTIVE for the analog supply VDDA.
      [15:0] VDDIO_ACTIVE — Indicates presence or absence of VDDIO supplies (i.e. other than VDDD, VDDA) on the device (supplies are numbered 0..n-1). Note that VDDIO supplies have basic (crude) supply detectors only. If separate, robust, brown-out detection is desired on IO supplies, on-chip or off-chip analog resources need to provide it. For these bits to work reliable, the supply must be within valid spec range (per datasheet) or held at ground. Any in-between voltage has an undefined result. '0': Supply is not present '1': Supply is present When multiple VDDIO supplies are present, they will be assigned in alphanumeric ascending order to these bits during implementation. For example 'vddusb, vddio_0, vddio_a, vbackup, vddio_r, vddio_1' are present then they will be assigned to these bits as below: 0: vbackup, 1: vddio_0, 2: vddio_1, 3: vddio_a, 4: vddio_r, 5: vddusb'
    0x8014 VDD_INTR — Supply detection interrupt register
      [31] VDDD_ACTIVE — The VDDD supply is always present during operation so a supply transition can not occur. This bit will always read back '1'.
      [30] VDDA_ACTIVE — Same as VDDIO_ACTIVE for the analog supply VDDA.
      [15:0] VDDIO_ACTIVE — Supply state change detected. '0': No change to supply detected '1': Change to supply detected
    0x8018 VDD_INTR_MASK — Supply detection interrupt mask register
      [31] VDDD_ACTIVE — Same as VDDIO_ACTIVE for the digital supply VDDD.
      [30] VDDA_ACTIVE — Same as VDDIO_ACTIVE for the analog supply VDDA.
      [15:0] VDDIO_ACTIVE — Masks supply interrupt on VDDIO. '0': VDDIO interrupt forwarding disabled '1': VDDIO interrupt forwarding enabled
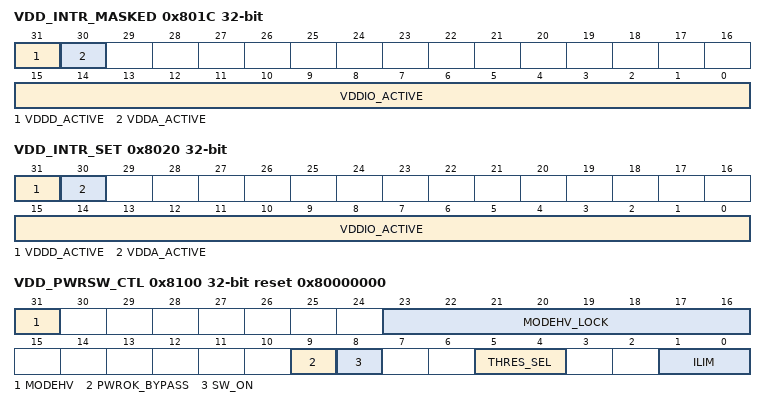
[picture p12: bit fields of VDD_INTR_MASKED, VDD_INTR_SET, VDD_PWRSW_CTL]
    0x801C VDD_INTR_MASKED ro — Supply detection interrupt masked register
      [31] VDDD_ACTIVE — Same as VDDIO_ACTIVE for the digital supply VDDD.
      [30] VDDA_ACTIVE — Same as VDDIO_ACTIVE for the analog supply VDDA.
      [15:0] VDDIO_ACTIVE — Supply transition detected AND masked '0': Interrupt was not forwarded to CPU '1': Interrupt occurred and was forwarded to CPU
    0x8020 VDD_INTR_SET — Supply detection interrupt set register
      [31] VDDD_ACTIVE — Same as VDDIO_ACTIVE for the digital supply VDDD.
      [30] VDDA_ACTIVE — Same as VDDIO_ACTIVE for the analog supply VDDA.
      [15:0] VDDIO_ACTIVE — Sets supply interrupt. '0': Interrupt state not affected '1': Interrupt set
    0x8024 VDD_PWRSW_STATUS ro — Power switch status
      [0] PWROK — Power Switch status.
    0x8100 VDD_PWRSW_CTL reset 0x80000000 — Power Switch control
      [31] MODEHV — Controls the bias circuit of 3.3V GPIOs 1 = 3.3V supply mode 0 = 1.8V supply mode This bit can only be set/clear if MODEHV_LOCK==0x3A. SW/FW must make sure that VDDIO is at 1.8V before clearing the bit to 0. Failure to do so can cause damage to the part.
      [23:16] MODEHV_LOCK — This byte must be set to 0x3A for MODEHV to be taken affect by HW. When this byte is not equal to 0x3A, writes to MODEHV are ignored and HW ignores the value of MODEHV. Do not change MODEHV in the same write cycle as setting/clearing the MODEHV_LOCK code; Do these in separate write cycles. Only write to this field when the VDDIO is at the correct voltage. Wrong setting of MODEHV can cause damage to the part.
      [9] PWROK_BYPASS — Switch is turn on and dc current limiting is disabled when PWROK_BYPASS and SW_ON are set to '1'
      [8] SW_ON — Switch enable signal.
      [5:4] THRES_SEL — Threshold select.
      [1:0] ILIM — Inrush current limit level select.
